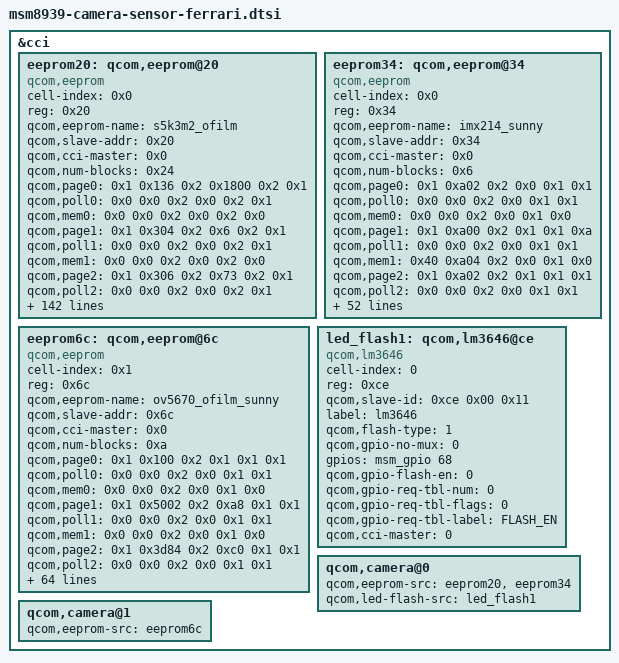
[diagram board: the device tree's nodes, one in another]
/* Copyright (c) 2014-2015, The Linux Foundation. All rights reserved.
 *
 * This program is free software; you can redistribute it and/or modify
 * it under the terms of the GNU General Public License version 2 and
 * only version 2 as published by the Free Software Foundation.
 *
 * This program is distributed in the hope that it will be useful,
 * but WITHOUT ANY WARRANTY; without even the implied warranty of
 * MERCHANTABILITY or FITNESS FOR A PARTICULAR PURPOSE.  See the
 * GNU General Public License for more details.
 */

&cci {

	eeprom20: qcom,eeprom@20 {
		cell-index = <0x0>;
		reg = <0x20>;
		qcom,eeprom-name = "s5k3m2_ofilm";
		compatible = "qcom,eeprom";
		qcom,slave-addr = <0x20>;
		qcom,cci-master = <0x0>;

		qcom,num-blocks = <0x24>;
		qcom,page0 = <0x1 0x136 0x2 0x1800 0x2 0x1>;
		qcom,poll0 = <0x0 0x0 0x2 0x0 0x2 0x1>;
		qcom,mem0 = <0x0 0x0 0x2 0x0 0x2 0x0>;
		qcom,page1 = <0x1 0x304 0x2 0x6 0x2 0x1>;
		qcom,poll1 = <0x0 0x0 0x2 0x0 0x2 0x1>;
		qcom,mem1 = <0x0 0x0 0x2 0x0 0x2 0x0>;
		qcom,page2 = <0x1 0x306 0x2 0x73 0x2 0x1>;
		qcom,poll2 = <0x0 0x0 0x2 0x0 0x2 0x1>;
		qcom,mem2 = <0x0 0x0 0x2 0x0 0x2 0x0>;
		qcom,page3 = <0x1 0x30c 0x2 0x4 0x2 0x1>;
		qcom,poll3 = <0x0 0x0 0x2 0x0 0x2 0x1>;
		qcom,mem3 = <0x0 0x0 0x2 0x0 0x2 0x0>;
		qcom,page4 = <0x1 0x30e 0x2 0x64 0x2 0x1>;
		qcom,poll4 = <0x0 0x0 0x2 0x0 0x2 0x1>;
		qcom,mem4 = <0x0 0x0 0x2 0x0 0x2 0x0>;
		qcom,page5 = <0x1 0x302 0x2 0x1 0x2 0x1>;
		qcom,poll5 = <0x0 0x0 0x2 0x0 0x2 0x1>;
		qcom,mem5 = <0x0 0x0 0x2 0x0 0x2 0x0>;

		cam_vdig-supply = <&pm8916_s4>;
		cam_vana-supply = <&pm8916_l17>;
		cam_vio-supply = <&pm8916_l6>;
		cam_vaf-supply = <&pm8916_l10>;

		qcom,cam-vreg-name = "cam_vdig", "cam_vio", "cam_vana", "cam_vaf";
		qcom,cam-vreg-type = <0x0 0x1 0x0 0x0>;
		qcom,cam-vreg-min-voltage = <0x200b20 0x0 0x2b7cd0 0x2ab980>;
		qcom,cam-vreg-max-voltage = <0x200b20 0x0 0x2b7cd0 0x2ab980>;
		qcom,cam-vreg-op-mode = <0x30d40 0x0 0x13880 0x186a0>;

		pinctrl-names = "cam_default", "cam_suspend";
		pinctrl-0 = <&cam_sensor_mclk0_default &cam_sensor_rear_default>;
		pinctrl-1 = <&cam_sensor_mclk0_sleep &cam_sensor_rear_sleep>;
		gpios =
			<&msm_gpio 0x1a 0x0>,
			<&msm_gpio 0x23 0x0>,
			<&msm_gpio 0x22 0x0>;

		qcom,gpio-reset = <0x1>;
		qcom,gpio-standby = <0x2>;
		qcom,gpio-req-tbl-num = <0x0 0x1 0x2>;
		qcom,gpio-req-tbl-flags = <0x1 0x0 0x0>;
		qcom,gpio-req-tbl-label = "CAMIF_MCLK0", "CAM_RESET0", "CAM_STANDBY0";
		qcom,gpio-set-tbl-num = <0x1 0x1>;
		qcom,gpio-set-tbl-flags = <0x0 0x2>;
		qcom,gpio-set-tbl-delay = <0x3e8 0xfa0>;
		qcom,csi-lane-assign = <0x4320>;
		qcom,csi-lane-mask = <0x1f>;
		qcom,cam-power-seq-type = "sensor_vreg", "sensor_vreg", "sensor_vreg", "sensor_vreg", "sensor_gpio", "sensor_gpio", "sensor_clk";
		qcom,cam-power-seq-val = "cam_vaf", "cam_vdig", "cam_vana", "cam_vio", "sensor_gpio_reset", "sensor_gpio_standby", "sensor_cam_mclk";
		qcom,cam-power-seq-cfg-val = <0x1 0x1 0x1 0x1 0x1 0x1 0x16e3600>;
		qcom,cam-power-seq-delay = <0x1 0x1 0x1 0x1 0x1e 0x1e 0x5>;

		status = "ok";
		clocks =
			<&clock_gcc clk_mclk0_clk_src>,
			<&clock_gcc clk_gcc_camss_mclk0_clk>;
		clock-names = "cam_src_clk", "cam_clk";

		qcom,page6 = <0x1 0x300 0x2 0x4 0x2 0x1>;
		qcom,poll6 = <0x0 0x0 0x2 0x0 0x2 0x1>;
		qcom,mem6 = <0x0 0x0 0x2 0x0 0x2 0x0>;
		qcom,page7 = <0x1 0x30a 0x2 0x1 0x2 0x1>;
		qcom,poll7 = <0x0 0x0 0x2 0x0 0x2 0x1>;
		qcom,mem7 = <0x0 0x0 0x2 0x0 0x2 0x0>;
		qcom,page8 = <0x1 0x308 0x2 0x8 0x2 0x1>;
		qcom,poll8 = <0x0 0x0 0x2 0x0 0x2 0x1>;
		qcom,mem8 = <0x0 0x0 0x2 0x0 0x2 0x0>;
		qcom,page9 = <0x1 0x100 0x2 0x100 0x2 0xa>;
		qcom,poll9 = <0x0 0x0 0x2 0x0 0x2 0x1>;
		qcom,mem9 = <0x0 0x0 0x2 0x0 0x2 0x0>;
		qcom,page10 = <0x1 0xa02 0x2 0x1f00 0x2 0x1>;
		qcom,poll10 = <0x0 0x0 0x2 0x0 0x2 0x1>;
		qcom,mem10 = <0x0 0x0 0x2 0x0 0x2 0x0>;
		qcom,page11 = <0x1 0xa00 0x2 0x100 0x2 0x1>;
		qcom,poll11 = <0x0 0x0 0x2 0x0 0x2 0x1>;
		qcom,mem11 = <0x2 0xa04 0x2 0x0 0x2 0x0>;
		qcom,page12 = <0x0 0x0 0x2 0x0 0x2 0x1>;
		qcom,poll12 = <0x0 0x0 0x2 0x0 0x2 0x1>;
		qcom,mem12 = <0x2 0xa06 0x2 0x0 0x2 0x0>;
		qcom,page13 = <0x0 0x0 0x2 0x0 0x2 0x1>;
		qcom,poll13 = <0x0 0x0 0x2 0x0 0x2 0x1>;
		qcom,mem13 = <0x2 0xa08 0x2 0x0 0x2 0x0>;
		qcom,page14 = <0x0 0x0 0x2 0x0 0x2 0x1>;
		qcom,poll14 = <0x0 0x0 0x2 0x0 0x2 0x1>;
		qcom,mem14 = <0x2 0xa0a 0x2 0x0 0x2 0x0>;
		qcom,page15 = <0x0 0x0 0x2 0x0 0x2 0x1>;
		qcom,poll15 = <0x0 0x0 0x2 0x0 0x2 0x1>;
		qcom,mem15 = <0x2 0xa0c 0x2 0x0 0x2 0x0>;
		qcom,page16 = <0x0 0x0 0x2 0x0 0x2 0x1>;
		qcom,poll16 = <0x0 0x0 0x2 0x0 0x2 0x1>;
		qcom,mem16 = <0x2 0xa0e 0x2 0x0 0x2 0x0>;
		qcom,page17 = <0x0 0x0 0x2 0x0 0x2 0x1>;
		qcom,poll17 = <0x0 0x0 0x2 0x0 0x2 0x1>;
		qcom,mem17 = <0x2 0xa10 0x2 0x0 0x2 0x0>;
		qcom,page18 = <0x0 0x0 0x2 0x0 0x2 0x1>;
		qcom,poll18 = <0x0 0x0 0x2 0x0 0x2 0x1>;
		qcom,mem18 = <0x2 0xa12 0x2 0x0 0x2 0x0>;
		qcom,page19 = <0x0 0x0 0x2 0x0 0x2 0x1>;
		qcom,poll19 = <0x0 0x0 0x2 0x0 0x2 0x1>;
		qcom,mem19 = <0x2 0xa14 0x2 0x0 0x2 0x0>;
		qcom,page20 = <0x0 0x0 0x2 0x0 0x2 0x1>;
		qcom,poll20 = <0x0 0x0 0x2 0x0 0x2 0x1>;
		qcom,mem20 = <0x2 0xa16 0x2 0x0 0x2 0x0>;
		qcom,page21 = <0x0 0x0 0x2 0x0 0x2 0x1>;
		qcom,poll21 = <0x0 0x0 0x2 0x0 0x2 0x1>;
		qcom,mem21 = <0x2 0xa18 0x2 0x0 0x2 0x0>;
		qcom,page22 = <0x0 0x0 0x2 0x0 0x2 0x1>;
		qcom,poll22 = <0x0 0x0 0x2 0x0 0x2 0x1>;
		qcom,mem22 = <0x2 0xa1a 0x2 0x0 0x2 0x0>;
		qcom,page23 = <0x0 0x0 0x2 0x0 0x2 0x1>;
		qcom,poll23 = <0x0 0x0 0x2 0x0 0x2 0x1>;
		qcom,mem23 = <0x2 0xa24 0x2 0x0 0x2 0x0>;
		qcom,page24 = <0x0 0x0 0x2 0x0 0x2 0x1>;
		qcom,poll24 = <0x0 0x0 0x2 0x0 0x2 0x1>;
		qcom,mem24 = <0x2 0xa26 0x2 0x0 0x2 0x0>;
		qcom,page25 = <0x0 0x0 0x2 0x0 0x2 0x1>;
		qcom,poll25 = <0x0 0x0 0x2 0x0 0x2 0x1>;
		qcom,mem25 = <0x2 0xa28 0x2 0x0 0x2 0x0>;
		qcom,page26 = <0x0 0x0 0x2 0x0 0x2 0x1>;
		qcom,poll26 = <0x0 0x0 0x2 0x0 0x2 0x1>;
		qcom,mem26 = <0x2 0xa2a 0x2 0x0 0x2 0x0>;
		qcom,page27 = <0x0 0x0 0x2 0x0 0x2 0x1>;
		qcom,poll27 = <0x0 0x0 0x2 0x0 0x2 0x1>;
		qcom,mem27 = <0x2 0xa2c 0x2 0x0 0x2 0x0>;
		qcom,page28 = <0x0 0x0 0x2 0x0 0x2 0x1>;
		qcom,poll28 = <0x0 0x0 0x2 0x0 0x2 0x1>;
		qcom,mem28 = <0x2 0xa2e 0x2 0x0 0x2 0x0>;
		qcom,page29 = <0x0 0x0 0x2 0x0 0x2 0x1>;
		qcom,poll29 = <0x0 0x0 0x2 0x0 0x2 0x1>;
		qcom,mem29 = <0x2 0xa30 0x2 0x0 0x2 0x0>;
		qcom,page30 = <0x0 0x0 0x2 0x0 0x2 0x1>;
		qcom,poll30 = <0x0 0x0 0x2 0x0 0x2 0x1>;
		qcom,mem30 = <0x2 0xa32 0x2 0x0 0x2 0x0>;
		qcom,page31 = <0x0 0x0 0x2 0x0 0x2 0x1>;
		qcom,poll31 = <0x0 0x0 0x2 0x0 0x2 0x1>;
		qcom,mem31 = <0x2 0xa34 0x2 0x0 0x2 0x0>;
		qcom,page32 = <0x0 0x0 0x2 0x0 0x2 0x1>;
		qcom,poll32 = <0x0 0x0 0x2 0x0 0x2 0x1>;
		qcom,mem32 = <0x2 0xa36 0x2 0x0 0x2 0x0>;
		qcom,page33 = <0x0 0x0 0x2 0x0 0x2 0x1>;
		qcom,poll33 = <0x0 0x0 0x2 0x0 0x2 0x1>;
		qcom,mem33 = <0x2 0xa38 0x2 0x0 0x2 0x0>;
		qcom,page34 = <0x0 0x0 0x2 0x0 0x2 0x1>;
		qcom,poll34 = <0x0 0x0 0x2 0x0 0x2 0x1>;
		qcom,mem34 = <0x2 0xa3a 0x2 0x0 0x2 0x0>;
		qcom,page35 = <0x1 0xa00 0x2 0x0 0x2 0x1>;
		qcom,poll35 = <0x0 0x0 0x2 0x0 0x2 0x1>;
		qcom,mem35 = <0x0 0x0 0x2 0x0 0x2 0x0>;
	};

	eeprom34: qcom,eeprom@34 {
		cell-index = <0x0>;
		reg = <0x34>;
		qcom,eeprom-name = "imx214_sunny";
		compatible = "qcom,eeprom";
		qcom,slave-addr = <0x34>;
		qcom,cci-master = <0x0>;

		qcom,num-blocks = <0x6>;
		qcom,page0 = <0x1 0xa02 0x2 0x0 0x1 0x1>;
		qcom,poll0 = <0x0 0x0 0x2 0x0 0x1 0x1>;
		qcom,mem0 = <0x0 0x0 0x2 0x0 0x1 0x0>;
		qcom,page1 = <0x1 0xa00 0x2 0x1 0x1 0xa>;
		qcom,poll1 = <0x0 0x0 0x2 0x0 0x1 0x1>;
		qcom,mem1 = <0x40 0xa04 0x2 0x0 0x1 0x0>;
		qcom,page2 = <0x1 0xa02 0x2 0x1 0x1 0x1>;
		qcom,poll2 = <0x0 0x0 0x2 0x0 0x1 0x1>;
		qcom,mem2 = <0x0 0x0 0x2 0x0 0x1 0x0>;
		qcom,page3 = <0x1 0xa00 0x2 0x1 0x1 0xa>;
		qcom,poll3 = <0x0 0x0 0x2 0x0 0x1 0x1>;
		qcom,mem3 = <0x40 0xa04 0x2 0x0 0x1 0x0>;
		qcom,page4 = <0x1 0xa02 0x2 0x2 0x1 0x1>;
		qcom,poll4 = <0x0 0x0 0x2 0x0 0x1 0x1>;
		qcom,mem4 = <0x0 0x0 0x2 0x0 0x1 0x0>;
		qcom,page5 = <0x1 0xa00 0x2 0x1 0x1 0xa>;
		qcom,poll5 = <0x0 0x0 0x2 0x0 0x1 0x1>;
		qcom,mem5 = <0x40 0xa04 0x2 0x0 0x1 0x0>;

		cam_vdig-supply = <&pm8916_s4>;
		cam_vana-supply = <&pm8916_l17>;
		cam_vio-supply = <&pm8916_l6>;
		cam_vaf-supply = <&pm8916_l10>;

		qcom,cam-vreg-name = "cam_vdig", "cam_vio", "cam_vana", "cam_vaf";
		qcom,cam-vreg-type = <0x0 0x1 0x0 0x0>;
		qcom,cam-vreg-min-voltage = <0x200b20 0x0 0x2b7cd0 0x2ab980>;
		qcom,cam-vreg-max-voltage = <0x200b20 0x0 0x2b7cd0 0x2ab980>;
		qcom,cam-vreg-op-mode = <0x30d40 0x0 0x13880 0x186a0>;

		pinctrl-names = "cam_default", "cam_suspend";
		pinctrl-0 = <&cam_sensor_mclk0_default &cam_sensor_rear_default>;
		pinctrl-1 = <&cam_sensor_mclk0_sleep &cam_sensor_rear_sleep>;

		gpios =
			<&msm_gpio 0x1a 0x0>,
			<&msm_gpio 0x23 0x0>,
			<&msm_gpio 0x22 0x0>;

		qcom,gpio-reset = <0x1>;
		qcom,gpio-standby = <0x2>;
		qcom,gpio-req-tbl-num = <0x0 0x1 0x2>;
		qcom,gpio-req-tbl-flags = <0x1 0x0 0x0>;
		qcom,gpio-req-tbl-label = "CAMIF_MCLK0", "CAM_RESET0", "CAM_STANDBY0";
		qcom,gpio-set-tbl-num = <0x1 0x1>;
		qcom,gpio-set-tbl-flags = <0x0 0x2>;
		qcom,gpio-set-tbl-delay = <0x3e8 0xfa0>;
		qcom,csi-lane-assign = <0x4320>;
		qcom,csi-lane-mask = <0x1f>;
		qcom,cam-power-seq-type = "sensor_vreg", "sensor_vreg", "sensor_vreg", "sensor_vreg", "sensor_gpio", "sensor_gpio", "sensor_clk";
		qcom,cam-power-seq-val = "cam_vaf", "cam_vdig", "cam_vana", "cam_vio", "sensor_gpio_reset", "sensor_gpio_standby", "sensor_cam_mclk";
		qcom,cam-power-seq-cfg-val = <0x1 0x1 0x1 0x1 0x1 0x1 0x16e3600>;
		qcom,cam-power-seq-delay = <0x1 0x1 0x1 0x1 0x1e 0x1e 0x5>;
		status = "ok";

		clocks =
			<&clock_gcc clk_mclk0_clk_src>,
			<&clock_gcc clk_gcc_camss_mclk0_clk>;
		clock-names = "cam_src_clk", "cam_clk";
	};

	eeprom6c: qcom,eeprom@6c {
		cell-index = <0x1>;
		reg = <0x6c>;
		qcom,eeprom-name = "ov5670_ofilm_sunny";
		compatible = "qcom,eeprom";
		qcom,slave-addr = <0x6c>;
		qcom,cci-master = <0x0>;
		qcom,num-blocks = <0xa>;

		qcom,page0 = <0x1 0x100 0x2 0x1 0x1 0x1>;
		qcom,poll0 = <0x0 0x0 0x2 0x0 0x1 0x1>;
		qcom,mem0 = <0x0 0x0 0x2 0x0 0x1 0x0>;
		qcom,page1 = <0x1 0x5002 0x2 0xa8 0x1 0x1>;
		qcom,poll1 = <0x0 0x0 0x2 0x0 0x1 0x1>;
		qcom,mem1 = <0x0 0x0 0x2 0x0 0x1 0x0>;
		qcom,page2 = <0x1 0x3d84 0x2 0xc0 0x1 0x1>;
		qcom,poll2 = <0x0 0x0 0x2 0x0 0x1 0x1>;
		qcom,mem2 = <0x0 0x0 0x2 0x0 0x1 0x0>;
		qcom,page3 = <0x1 0x3d88 0x2 0x70 0x1 0x1>;
		qcom,poll3 = <0x0 0x0 0x2 0x0 0x1 0x1>;
		qcom,mem3 = <0x0 0x3d00 0x2 0x0 0x1 0x0>;
		qcom,page4 = <0x1 0x3d89 0x2 0x10 0x1 0x1>;
		qcom,poll4 = <0x0 0x0 0x2 0x0 0x1 0x1>;
		qcom,mem4 = <0x0 0x3d00 0x2 0x0 0x1 0x0>;
		qcom,page5 = <0x1 0x3d8a 0x2 0x70 0x1 0x1>;
		qcom,poll5 = <0x0 0x0 0x2 0x0 0x1 0x1>;
		qcom,mem5 = <0x0 0x3d00 0x2 0x0 0x1 0x0>;
		qcom,page6 = <0x1 0x3d8b 0x2 0x29 0x1 0x1>;
		qcom,poll6 = <0x0 0x0 0x2 0x0 0x1 0x1>;
		qcom,mem6 = <0x0 0x3d00 0x2 0x0 0x1 0x0>;
		qcom,page7 = <0x1 0x3d81 0x2 0x1 0x1 0x5>;
		qcom,poll7 = <0x0 0x0 0x2 0x0 0x1 0x1>;
		qcom,mem7 = <0x1a 0x7010 0x2 0x0 0x1 0x1>;
		qcom,page8 = <0x1 0x5002 0x2 0xaa 0x1 0x1>;
		qcom,poll8 = <0x0 0x0 0x2 0x0 0x1 0x1>;
		qcom,mem8 = <0x0 0x0 0x2 0x0 0x1 0x0>;
		qcom,page9 = <0x1 0x100 0x2 0x0 0x1 0x1>;
		qcom,poll9 = <0x0 0x0 0x2 0x0 0x1 0x1>;
		qcom,mem9 = <0x0 0x0 0x2 0x0 0x1 0x0>;

		cam_vdig-supply = <&pm8916_s4>;
		cam_vana-supply = <&pm8916_l17>;
		cam_vio-supply = <&pm8916_l6>;
		cam_vaf-supply = <&pm8916_l10>;

		qcom,cam-vreg-name = "cam_vdig", "cam_vio", "cam_vana", "cam_vaf";
		qcom,cam-vreg-type = <0x0 0x1 0x0 0x0>;
		qcom,cam-vreg-min-voltage = <0x200b20 0x0 0x2b7cd0 0x2ab980>;
		qcom,cam-vreg-max-voltage = <0x200b20 0x0 0x2b7cd0 0x2ab980>;
		qcom,cam-vreg-op-mode = <0x30d40 0x0 0x13880 0x186a0>;

		pinctrl-names = "cam_default", "cam_suspend";
		pinctrl-0 = <&cam_sensor_mclk1_default &cam_sensor_front_default>;
		pinctrl-1 = <&cam_sensor_mclk1_sleep &cam_sensor_front_sleep>;

		gpios =
			<&msm_gpio 0x1b 0x0>,
			<&msm_gpio 0x1c 0x0>,
			<&msm_gpio 0x21 0x0>;

		qcom,gpio-reset = <0x1>;
		qcom,gpio-standby = <0x2>;
		qcom,gpio-req-tbl-num = <0x0 0x1 0x2>;
		qcom,gpio-req-tbl-flags = <0x1 0x0 0x0>;
		qcom,gpio-req-tbl-label = "CAMIF_MCLK1", "CAM_RESET1", "CAM_STANDBY1";
		qcom,gpio-set-tbl-num = <0x1 0x1>;
		qcom,gpio-set-tbl-flags = <0x0 0x2>;
		qcom,gpio-set-tbl-delay = <0x3e8 0xfa0>;
		qcom,csi-lane-assign = <0x4320>;
		qcom,csi-lane-mask = <0x7>;
		qcom,cam-power-seq-type = "sensor_vreg", "sensor_vreg", "sensor_vreg", "sensor_vreg", "sensor_gpio", "sensor_gpio", "sensor_clk";
		qcom,cam-power-seq-val = "cam_vaf", "cam_vdig", "cam_vana", "cam_vio", "sensor_gpio_reset", "sensor_gpio_standby", "sensor_cam_mclk";
		qcom,cam-power-seq-cfg-val = <0x1 0x1 0x1 0x1 0x1 0x1 0x16e3600>;
		qcom,cam-power-seq-delay = <0x1 0x1 0x1 0x1 0x1e 0x1e 0x5>;

		status = "ok";
		clocks =
			<&clock_gcc clk_mclk1_clk_src>,
			<&clock_gcc clk_gcc_camss_mclk1_clk>;
		clock-names = "cam_src_clk", "cam_clk";
	};

	led_flash1: qcom,lm3646@ce {
		cell-index = <0>;
		reg = <0xce>;
		qcom,slave-id = <0xce 0x00 0x11>;
		compatible = "qcom,lm3646";
		label = "lm3646";
		qcom,flash-type = <1>;
		qcom,gpio-no-mux = <0>;
		gpios = <&msm_gpio 68 0>;
		qcom,gpio-flash-en = <0>;
		qcom,gpio-req-tbl-num = <0>;
		qcom,gpio-req-tbl-flags = <0>;
		qcom,gpio-req-tbl-label = "FLASH_EN";
		qcom,cci-master = <0>;
	};

	qcom,camera@0 {
		qcom,eeprom-src = <&eeprom20 &eeprom34>;
		qcom,led-flash-src = <&led_flash1>;
	};

	qcom,camera@1 {
		qcom,eeprom-src = <&eeprom6c>;
	};

	/delete-node/ qcom,camera@78;

};
